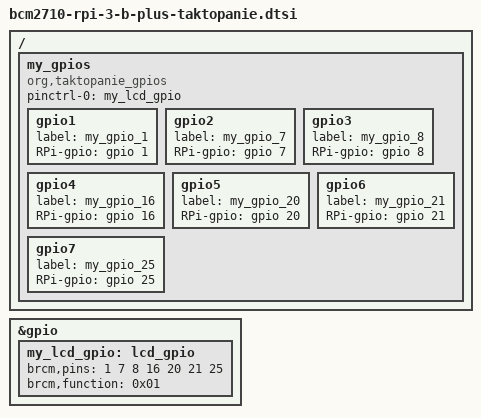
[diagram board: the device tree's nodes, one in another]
/ {
        
        my_gpios{
                compatible = "org,taktopanie_gpios";
                pinctrl-names = "default";
                pinctrl-0 = <&my_lcd_gpio>;

                gpio1{
                        label = "my_gpio_1";
                        RPi-gpio = <&gpio 1 GPIO_ACTIVE_HIGH>;
                };

                gpio2{
                        label = "my_gpio_7";
                        RPi-gpio = <&gpio 7 GPIO_ACTIVE_HIGH>;
 
                };

                gpio3{
                        label = "my_gpio_8";
                        RPi-gpio = <&gpio 8 GPIO_ACTIVE_HIGH>;
                };

                gpio4{
                        label = "my_gpio_16";
                        RPi-gpio = <&gpio 16 GPIO_ACTIVE_HIGH>;
                };

                gpio5{
                        label = "my_gpio_20";
                        RPi-gpio = <&gpio 20 GPIO_ACTIVE_HIGH>;
                };

                gpio6{
                        label = "my_gpio_21";
                        RPi-gpio = <&gpio 21 GPIO_ACTIVE_HIGH>;
                };

                gpio7{
                        label = "my_gpio_25";
                        RPi-gpio = <&gpio 25 GPIO_ACTIVE_HIGH>;
                };
        };



};



&gpio {
        my_lcd_gpio: lcd_gpio {
                brcm,pins = <1 7 8 16 20 21 25>;
                brcm,function = <0x01>;
        }; 
};
